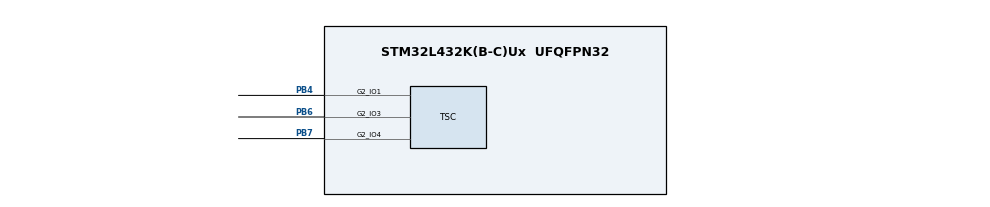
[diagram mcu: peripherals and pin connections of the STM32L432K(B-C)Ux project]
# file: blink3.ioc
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Mcu.Family=STM32L4
Mcu.Name=STM32L432K(B-C)Ux
Mcu.Package=UFQFPN32
NVIC.PriorityGroup=NVIC_PRIORITYGROUP_4
NVIC.TSC_IRQn=true\:0\:0\:false\:false\:true\:true
PA13\ (JTMS-SWDIO).Mode=Serial_Wire
PA13\ (JTMS-SWDIO).Signal=SYS_JTMS-SWDIO
PA14\ (JTCK-SWCLK).Mode=Serial_Wire
PA14\ (JTCK-SWCLK).Signal=SYS_JTCK-SWCLK
PB4\ (NJTRST).Mode=G2_IO1-Channel
PB4\ (NJTRST).Signal=TSC_G2_IO1
PB6.Mode=G2_IO3-Channel
PB6.Signal=TSC_G2_IO3
PB7.Mode=G2_IO4-Sampling
PB7.Signal=TSC_G2_IO4
ProjectManager.HeapSize=0x200
ProjectManager.StackSize=0x400
ProjectManager.TargetToolchain=Makefile
RCC.HSE_VALUE=8000000
RCC.HSI48_VALUE=48000000
RCC.HSI_VALUE=16000000
RCC.LSE_VALUE=32768
RCC.MSI_VALUE=4000000
RCC.VCOOutputFreq_Value=32000000
TSC.ChannelIOs-G2_IO1-Channel=TSC_GROUP2_IO1
TSC.ChannelIOs-G2_IO3-Channel=TSC_GROUP2_IO3
TSC.SamplingIOs=TSC_GROUP2_IO4
board=custom

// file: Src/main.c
/* USER CODE BEGIN Header */
/**
  ******************************************************************************
  * @file           : main.c
  * @brief          : Main program body
  ******************************************************************************
  ** This notice applies to any and all portions of this file
  * that are not between comment pairs USER CODE BEGIN and
  * USER CODE END. Other portions of this file, whether
  * inserted by the user or by software development tools
  * are owned by their respective copyright owners.
  *
  * COPYRIGHT(c) 2019 STMicroelectronics
  *
  * Redistribution and use in source and binary forms, with or without modification,
  * are permitted provided that the following conditions are met:
  *   1. Redistributions of source code must retain the above copyright notice,
  *      this list of conditions and the following disclaimer.
  *   2. Redistributions in binary form must reproduce the above copyright notice,
  *      this list of conditions and the following disclaimer in the documentation
  *      and/or other materials provided with the distribution.
  *   3. Neither the name of STMicroelectronics nor the names of its contributors
  *      may be used to endorse or promote products derived from this software
  *      without specific prior written permission.
  *
  * THIS SOFTWARE IS PROVIDED BY THE COPYRIGHT HOLDERS AND CONTRIBUTORS "AS IS"
  * AND ANY EXPRESS OR IMPLIED WARRANTIES, INCLUDING, BUT NOT LIMITED TO, THE
  * IMPLIED WARRANTIES OF MERCHANTABILITY AND FITNESS FOR A PARTICULAR PURPOSE ARE
  * DISCLAIMED. IN NO EVENT SHALL THE COPYRIGHT HOLDER OR CONTRIBUTORS BE LIABLE
  * FOR ANY DIRECT, INDIRECT, INCIDENTAL, SPECIAL, EXEMPLARY, OR CONSEQUENTIAL
  * DAMAGES (INCLUDING, BUT NOT LIMITED TO, PROCUREMENT OF SUBSTITUTE GOODS OR
  * SERVICES; LOSS OF USE, DATA, OR PROFITS; OR BUSINESS INTERRUPTION) HOWEVER
  * CAUSED AND ON ANY THEORY OF LIABILITY, WHETHER IN CONTRACT, STRICT LIABILITY,
  * OR TORT (INCLUDING NEGLIGENCE OR OTHERWISE) ARISING IN ANY WAY OUT OF THE USE
  * OF THIS SOFTWARE, EVEN IF ADVISED OF THE POSSIBILITY OF SUCH DAMAGE.
  *
  ******************************************************************************
  */
/* USER CODE END Header */

#include "main.h"

TSC_HandleTypeDef htsc;

void SystemClock_Config(void);
static void MX_GPIO_Init(void);
static void MX_TSC_Init(void);
/* USER CODE BEGIN PFP */

void HAL_TSC_ConvCpltCallback(TSC_HandleTypeDef* htsc);
/* USER CODE END PFP */

int main(void)
{

  /* MCU Configuration--------------------------------------------------------*/

  /* Reset of all peripherals, Initializes the Flash interface and the Systick. */
  HAL_Init();

  /* Configure the system clock */
  SystemClock_Config();

  /* Initialize all configured peripherals */
  MX_GPIO_Init();
  MX_TSC_Init();
  /* USER CODE BEGIN 2 */

  // Touch sensing inputs
  // XXX: not needed when specified during INIT?
#if 0
  IoConfig.ChannelIOs  =(TSC_GROUP2_IO1|TSC_GROUP2_IO3);
  IoConfig.SamplingIOs = TSC_GROUP2_IO4;
  IoConfig.ShieldIOs = 0;
  if (HAL_TSC_IOConfig(&htsc, &IoConfig) != HAL_OK)
  {
    /* Initialization Error */
    Error_Handler();
  }
#endif

  /* Discharge the touch-sensing IOs */
  HAL_TSC_IODischarge(&htsc, ENABLE);
  HAL_Delay(1); /* 1 ms is more than enough to discharge all capacitors */

  /* Start TSC acquisition process */
  if (HAL_TSC_Start_IT(&htsc) != HAL_OK)
  {
    /* Acquisition Error */
    Error_Handler();
  }

  // PA1, use analog- as output
   // PA6, LED_ENABLE
	GPIO_InitTypeDef GPIO_InitStruct;
	GPIO_InitStruct.Pin = GPIO_PIN_0 | GPIO_PIN_1 | GPIO_PIN_6;
	GPIO_InitStruct.Mode = GPIO_MODE_OUTPUT_PP;
	GPIO_InitStruct.Speed = GPIO_SPEED_LOW;
	HAL_GPIO_Init(GPIOA, &GPIO_InitStruct);

  /* USER CODE END 2 */

  /* Infinite loop */
  while (1)
  {

    /* USER CODE BEGIN 3 */
    HAL_GPIO_WritePin(GPIOA, GPIO_PIN_6, GPIO_PIN_SET);
    HAL_GPIO_WritePin(GPIOA, GPIO_PIN_1, GPIO_PIN_SET);
    HAL_Delay(500);

    HAL_GPIO_WritePin(GPIOA, GPIO_PIN_6, GPIO_PIN_RESET);
    HAL_GPIO_WritePin(GPIOA, GPIO_PIN_1, GPIO_PIN_RESET);
    HAL_Delay(500);
  }
  /* USER CODE END 3 */
}

void SystemClock_Config(void)
{
  RCC_OscInitTypeDef RCC_OscInitStruct = {0};
  RCC_ClkInitTypeDef RCC_ClkInitStruct = {0};

  /**Initializes the CPU, AHB and APB busses clocks
  */
  RCC_OscInitStruct.OscillatorType = RCC_OSCILLATORTYPE_MSI;
  RCC_OscInitStruct.MSIState = RCC_MSI_ON;
  RCC_OscInitStruct.MSICalibrationValue = 0;
  RCC_OscInitStruct.MSIClockRange = RCC_MSIRANGE_6;
  RCC_OscInitStruct.PLL.PLLState = RCC_PLL_NONE;
  if (HAL_RCC_OscConfig(&RCC_OscInitStruct) != HAL_OK)
  {
    Error_Handler();
  }
  /**Initializes the CPU, AHB and APB busses clocks
  */
  RCC_ClkInitStruct.ClockType = RCC_CLOCKTYPE_HCLK|RCC_CLOCKTYPE_SYSCLK
                              |RCC_CLOCKTYPE_PCLK1|RCC_CLOCKTYPE_PCLK2;
  RCC_ClkInitStruct.SYSCLKSource = RCC_SYSCLKSOURCE_MSI;
  RCC_ClkInitStruct.AHBCLKDivider = RCC_SYSCLK_DIV1;
  RCC_ClkInitStruct.APB1CLKDivider = RCC_HCLK_DIV1;
  RCC_ClkInitStruct.APB2CLKDivider = RCC_HCLK_DIV1;

  if (HAL_RCC_ClockConfig(&RCC_ClkInitStruct, FLASH_LATENCY_0) != HAL_OK)
  {
    Error_Handler();
  }
  /**Configure the main internal regulator output voltage
  */
  if (HAL_PWREx_ControlVoltageScaling(PWR_REGULATOR_VOLTAGE_SCALE1) != HAL_OK)
  {
    Error_Handler();
  }
}

static void MX_TSC_Init(void)
{

  /**Configure the TSC peripheral
  */
  htsc.Instance = TSC;
  htsc.Init.CTPulseHighLength = TSC_CTPH_2CYCLES;
  htsc.Init.CTPulseLowLength = TSC_CTPL_2CYCLES;
  htsc.Init.SpreadSpectrum = DISABLE;
  htsc.Init.SpreadSpectrumDeviation = 1;
  htsc.Init.SpreadSpectrumPrescaler = TSC_SS_PRESC_DIV1;
  htsc.Init.PulseGeneratorPrescaler = TSC_PG_PRESC_DIV4;
  htsc.Init.MaxCountValue = TSC_MCV_8191;
  htsc.Init.IODefaultMode = TSC_IODEF_OUT_PP_LOW;
  htsc.Init.SynchroPinPolarity = TSC_SYNC_POLARITY_FALLING;
  htsc.Init.AcquisitionMode = TSC_ACQ_MODE_NORMAL;
  htsc.Init.MaxCountInterrupt = DISABLE;
  htsc.Init.ChannelIOs = TSC_GROUP2_IO1|TSC_GROUP2_IO3;
  htsc.Init.ShieldIOs = 0;
  htsc.Init.SamplingIOs = TSC_GROUP2_IO4;
  if (HAL_TSC_Init(&htsc) != HAL_OK)
  {
    Error_Handler();
  }

}

static void MX_GPIO_Init(void)
{

  /* GPIO Ports Clock Enable */
  __HAL_RCC_GPIOA_CLK_ENABLE();
  __HAL_RCC_GPIOB_CLK_ENABLE();

}

/* USER CODE BEGIN 4 */

// Interrupt for Touch Sensing Controller
void HAL_TSC_ConvCpltCallback(TSC_HandleTypeDef* htsc)
{
  /* Discharge the touch-sensing IOs */
  HAL_TSC_IODischarge(htsc, ENABLE);
  /* Note: a delay can be added here */
  /* wait 100us */
  uint32_t wait_loop_index = (SystemCoreClock / 10000);
  while (wait_loop_index != 0)
  {
    wait_loop_index--;
  }

  /*##-6- Check if the acquisition is correct (no max count) #################*/
  if (HAL_TSC_GroupGetStatus(htsc, TSC_GROUP2_IDX) == TSC_GROUP_COMPLETED)
  {
    /*##-7- Read the acquisition value */
    volatile uint32_t val = HAL_TSC_GroupGetValue(htsc, TSC_GROUP2_IDX);
    volatile uint32_t two = val;

#if 0
    /* Note: Show the touch activity on LEDs.
       The threshold values are indicative and may need to be adjusted */
    if (uhTSCAcquisitionValue < TSCx_TS1_MAXTHRESHOLD)
    {
      BSP_LED_On(LED1);
    }
    else
    {
      BSP_LED_Off(LED1);
    }
#endif

  }

  /* Re-start acquisition  */
  if (HAL_TSC_Start_IT(htsc) != HAL_OK)
  {
    /* Acquisition Error */
    Error_Handler();
  }
}

/* USER CODE END 4 */

void Error_Handler(void)
{
}

/************************ (C) COPYRIGHT STMicroelectronics *****END OF FILE****/
